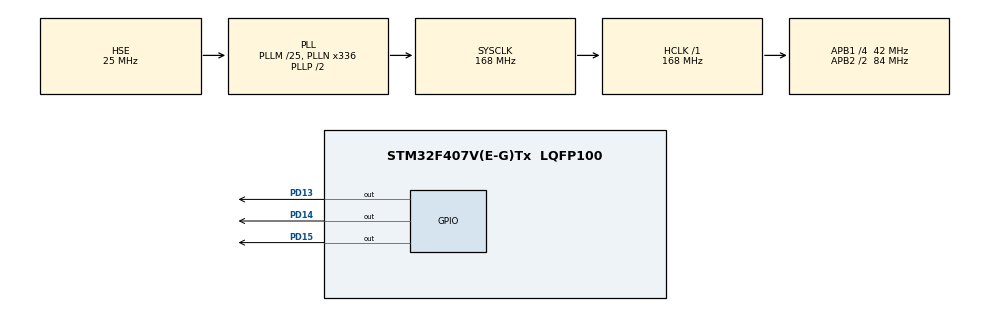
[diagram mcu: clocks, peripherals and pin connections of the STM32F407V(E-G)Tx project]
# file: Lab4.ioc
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FREERTOS.Tasks01=blink01,24,128,StartBlink01,Default,NULL,Dynamic,NULL,NULL;blink02,16,128,StartBlink02,Default,NULL,Dynamic,NULL,NULL
IWDG.Prescaler=IWDG_PRESCALER_64
Mcu.Family=STM32F4
Mcu.Name=STM32F407V(E-G)Tx
Mcu.Package=LQFP100
NVIC.PriorityGroup=NVIC_PRIORITYGROUP_4
NVIC.TIM6_DAC_IRQn=true\:0\:0\:false\:false\:true\:false\:false\:true
NVIC.TimeBase=TIM6_DAC_IRQn
NVIC.TimeBaseIP=TIM6
PA13.Mode=JTAG_5_pins
PA13.Signal=SYS_JTMS-SWDIO
PA14.Mode=JTAG_5_pins
PA14.Signal=SYS_JTCK-SWCLK
PA15.Mode=JTAG_5_pins
PA15.Signal=SYS_JTDI
PB3.Mode=JTAG_5_pins
PB3.Signal=SYS_JTDO-SWO
PB4.Mode=JTAG_5_pins
PB4.Signal=SYS_JTRST
PD13.GPIO_Speed=GPIO_SPEED_FREQ_HIGH
PD13.Signal=GPIO_Output
PD14.GPIO_Speed=GPIO_SPEED_FREQ_HIGH
PD14.Signal=GPIO_Output
PD15.GPIO_Speed=GPIO_SPEED_FREQ_HIGH
PD15.Signal=GPIO_Output
PH0-OSC_IN.Mode=HSE-External-Oscillator
PH0-OSC_IN.Signal=RCC_OSC_IN
PH1-OSC_OUT.Mode=HSE-External-Oscillator
PH1-OSC_OUT.Signal=RCC_OSC_OUT
ProjectManager.HeapSize=0x200
ProjectManager.StackSize=0x400
ProjectManager.TargetToolchain=STM32CubeIDE
RCC.48MHZClocksFreq_Value=84000000
RCC.AHBFreq_Value=168000000
RCC.APB1CLKDivider=RCC_HCLK_DIV4
RCC.APB1Freq_Value=42000000
RCC.APB1TimFreq_Value=84000000
RCC.APB2CLKDivider=RCC_HCLK_DIV2
RCC.APB2Freq_Value=84000000
RCC.APB2TimFreq_Value=168000000
RCC.CortexFreq_Value=168000000
RCC.HCLKFreq_Value=168000000
RCC.HSE_VALUE=25000000
RCC.HSI_VALUE=16000000
RCC.LSE_VALUE=32768
RCC.PLLM=25
RCC.PLLN=336
RCC.PLLSourceVirtual=RCC_PLLSOURCE_HSE
RCC.SYSCLKFreq_VALUE=168000000
RCC.SYSCLKSource=RCC_SYSCLKSOURCE_PLLCLK
RCC.VCOOutputFreq_Value=336000000
VP_FREERTOS_VS_CMSIS_V2.Mode=CMSIS_V2
VP_IWDG_VS_IWDG.Mode=IWDG_Activate
VP_SYS_VS_tim6.Mode=TIM6
board=custom

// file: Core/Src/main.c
/* USER CODE BEGIN Header */
/**
  ******************************************************************************
  * @file           : main.c
  * @brief          : Main program body
  ******************************************************************************
  * @attention
  *
  * <h2><center>&copy; Copyright (c) 2020 STMicroelectronics.
  * All rights reserved.</center></h2>
  *
  * This software component is licensed by ST under BSD 3-Clause license,
  * the "License"; You may not use this file except in compliance with the
  * License. You may obtain a copy of the License at:
  *                        opensource.org/licenses/BSD-3-Clause
  *
  ******************************************************************************
  */
/* USER CODE END Header */
#include "main.h"
#include "cmsis_os.h"
#include "iwdg.h"
#include "gpio.h"

/* USER CODE BEGIN Includes */
#include "SDK/interface.h"
/* USER CODE END Includes */

void SystemClock_Config(void);
void MX_FREERTOS_Init(void);

int main(void)
{

  /* MCU Configuration--------------------------------------------------------*/

  /* Reset of all peripherals, Initializes the Flash interface and the Systick. */
  HAL_Init();

  /* Configure the system clock */
  SystemClock_Config();

  /* USER CODE BEGIN SysInit */
  HAL_NVIC_SetPriorityGrouping(NVIC_PRIORITYGROUP_2);
  /* USER CODE END SysInit */

  /* Initialize all configured peripherals */
  MX_GPIO_Init();
  MX_IWDG_Init();
  /* USER CODE BEGIN 2 */

  osKernelInitialize();  /* Call init function for freertos objects (in freertos.c) */
  MX_FREERTOS_Init();

  //SDK_INT_Init();
  SDK_MAIN_Wrapper();

  /* USER CODE END 2 */

  /* Init scheduler */
  /* Start scheduler */
  //osKernelStart();

  /* We should never get here as control is now taken by the scheduler */
  /* Infinite loop */
  while (1)
  {

  }
}

void SystemClock_Config(void)
{
  RCC_OscInitTypeDef RCC_OscInitStruct = {0};
  RCC_ClkInitTypeDef RCC_ClkInitStruct = {0};

  /** Configure the main internal regulator output voltage
  */
  __HAL_RCC_PWR_CLK_ENABLE();
  __HAL_PWR_VOLTAGESCALING_CONFIG(PWR_REGULATOR_VOLTAGE_SCALE1);
  /** Initializes the RCC Oscillators according to the specified parameters
  * in the RCC_OscInitTypeDef structure.
  */
  RCC_OscInitStruct.OscillatorType = RCC_OSCILLATORTYPE_LSI|RCC_OSCILLATORTYPE_HSE;
  RCC_OscInitStruct.HSEState = RCC_HSE_ON;
  RCC_OscInitStruct.LSIState = RCC_LSI_ON;
  RCC_OscInitStruct.PLL.PLLState = RCC_PLL_ON;
  RCC_OscInitStruct.PLL.PLLSource = RCC_PLLSOURCE_HSE;
  RCC_OscInitStruct.PLL.PLLM = 25;
  RCC_OscInitStruct.PLL.PLLN = 336;
  RCC_OscInitStruct.PLL.PLLP = RCC_PLLP_DIV2;
  RCC_OscInitStruct.PLL.PLLQ = 4;
  if (HAL_RCC_OscConfig(&RCC_OscInitStruct) != HAL_OK)
  {
    Error_Handler();
  }
  /** Initializes the CPU, AHB and APB buses clocks
  */
  RCC_ClkInitStruct.ClockType = RCC_CLOCKTYPE_HCLK|RCC_CLOCKTYPE_SYSCLK
                              |RCC_CLOCKTYPE_PCLK1|RCC_CLOCKTYPE_PCLK2;
  RCC_ClkInitStruct.SYSCLKSource = RCC_SYSCLKSOURCE_PLLCLK;
  RCC_ClkInitStruct.AHBCLKDivider = RCC_SYSCLK_DIV1;
  RCC_ClkInitStruct.APB1CLKDivider = RCC_HCLK_DIV4;
  RCC_ClkInitStruct.APB2CLKDivider = RCC_HCLK_DIV2;

  if (HAL_RCC_ClockConfig(&RCC_ClkInitStruct, FLASH_LATENCY_5) != HAL_OK)
  {
    Error_Handler();
  }
}

 /**
  * @brief  Period elapsed callback in non blocking mode
  * @note   This function is called  when TIM6 interrupt took place, inside
  * HAL_TIM_IRQHandler(). It makes a direct call to HAL_IncTick() to increment
  * a global variable "uwTick" used as application time base.
  * @param  htim : TIM handle
  * @retval None
  */
void HAL_TIM_PeriodElapsedCallback(TIM_HandleTypeDef *htim)
{
  if (htim->Instance == TIM6) {
    HAL_IncTick();
    SDK_SYS_Tick();
  }
}

void Error_Handler(void)
{
}

/************************ (C) COPYRIGHT STMicroelectronics *****END OF FILE****/
